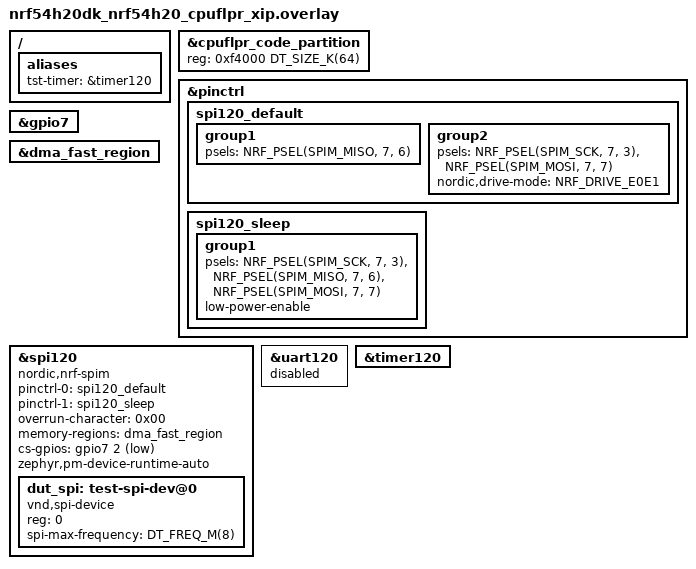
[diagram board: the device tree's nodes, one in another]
/*
 * Copyright (c) 2026 Nordic Semiconductor ASA
 *
 * SPDX-License-Identifier: LicenseRef-Nordic-5-Clause
 */

/* Required loopbacks:
 * P7.06 <-> P7.07
 */

&cpuflpr_code_partition {
	reg = <0xf4000 DT_SIZE_K(64)>;
};

/ {
	aliases {
		tst-timer = &timer120;
	};
};

&pinctrl {
	spi120_default: spi120_default {
		group1 {
			psels = <NRF_PSEL(SPIM_MISO, 7, 6)>;
		};

		group2 {
			psels = <NRF_PSEL(SPIM_SCK, 7, 3)>,
				<NRF_PSEL(SPIM_MOSI, 7, 7)>;
			nordic,drive-mode = <NRF_DRIVE_E0E1>;
		};
	};

	spi120_sleep: spi120_sleep {
		group1 {
			psels = <NRF_PSEL(SPIM_SCK, 7, 3)>,
				<NRF_PSEL(SPIM_MISO, 7, 6)>,
				<NRF_PSEL(SPIM_MOSI, 7, 7)>;
			low-power-enable;
		};
	};
};

&gpio7 {
	status = "okay";
};

&dma_fast_region {
	status = "okay";
};

&spi120 {
	compatible = "nordic,nrf-spim";
	status = "okay";
	pinctrl-0 = <&spi120_default>;
	pinctrl-1 = <&spi120_sleep>;
	pinctrl-names = "default", "sleep";
	overrun-character = <0x00>;
	memory-regions = <&dma_fast_region>;
	cs-gpios = <&gpio7 2 GPIO_ACTIVE_LOW>;
	zephyr,pm-device-runtime-auto;

	dut_spi: test-spi-dev@0 {
		compatible = "vnd,spi-device";
		reg = <0>;
		spi-max-frequency = <DT_FREQ_M(8)>;
	};
};

&uart120 {
	status = "disabled";
};

&timer120 {
	status = "okay";
};
